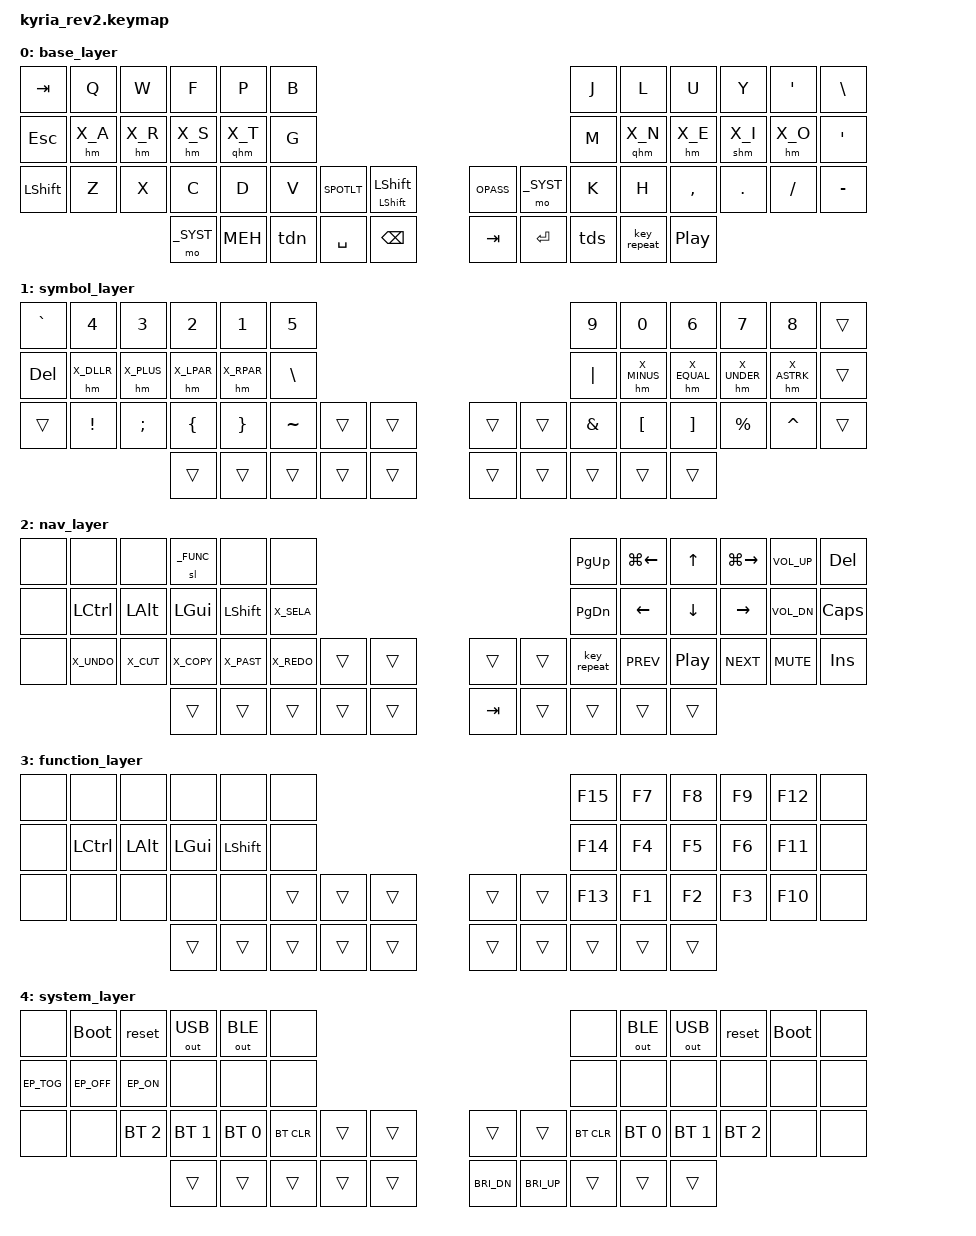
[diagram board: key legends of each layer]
/*
 * Copyright (c) 2020 The ZMK Contributors
 *
 * SPDX-License-Identifier: MIT
 */

#include <behaviors.dtsi>
#include <dt-bindings/zmk/keys.h>
#include <dt-bindings/zmk/bt.h>
#include <dt-bindings/zmk/outputs.h>
#include <dt-bindings/zmk/ext_power.h>
#include "halcyoncorsair.h"

// Encoder resolutions
&left_encoder   { resolution = <2>; };
&right_encoder  { resolution = <2>; };

&lt {
    tapping-term-ms = <250>;
    flavor = "tap-preferred";
};

&mt {
    tapping-term-ms = <200>;
};

&sk {
     release-after-ms = <1000>;
     quick-release;
};

&sl {
    /delete-property/ quick-release;
};

&caps_word {
    continue-list = <UNDERSCORE MINUS PIPE>; // BSPC
};

/ {
    behaviors {
        bhm: balanced_homerow_mods {
            compatible = "zmk,behavior-hold-tap";
            label = "HOMEROW_MODS";
            #binding-cells = <2>;
            tapping-term-ms = <200>;    // <---[[moderate duration]]
            quick-tap-ms = <0>;
            flavor = "balanced";
            bindings = <&kp>, <&kp>;
        };
        shm: homerow_mods {
            compatible = "zmk,behavior-hold-tap";
            label = "HOMEROW_MODS";
            #binding-cells = <2>;
            tapping-term-ms = <300>;
            quick-tap-ms = <0>;
            flavor = "tap-preferred";
            bindings = <&kp>, <&kp>;
        };
        hm: homerow_mods {
            compatible = "zmk,behavior-hold-tap";
            label = "HOMEROW_MODS";
            #binding-cells = <2>;
            tapping-term-ms = <250>;
            quick-tap-ms = <0>;
            flavor = "tap-preferred";
            bindings = <&kp>, <&kp>;
        };
        qhm: homerow_mods {
            compatible = "zmk,behavior-hold-tap";
            label = "QUICK_HOMEROW_MODS";
            #binding-cells = <2>;
            tapping-term-ms = <200>;
            quick-tap-ms = <0>;
            flavor = "tap-preferred";
            bindings = <&kp>, <&kp>;
        };
        ss: sticky_shift {
            compatible = "zmk,behavior-hold-tap";
            label = "STICKY_SHIFT";
            #binding-cells = <2>;
            tapping-term-ms = <150>;
            quick-tap-ms = <0>;
            flavor = "tap-preferred";
            bindings = <&kp>, <&sk>;
        };
		tdn: tap_dance_navi {
            compatible = "zmk,behavior-tap-dance";
            label = "TAP_DANCE_NAVI";
            #binding-cells = <0>;
            tapping-term-ms = <200>;
            bindings = <&mo _NAVI>, <&tog _NAVI>;
        };
		tds: tap_dance_symb {
            compatible = "zmk,behavior-tap-dance";
            label = "TAP_DANCE_SYMB";
            #binding-cells = <0>;
            tapping-term-ms = <200>;
            bindings = <&mo _SYMB>, <&tog _SYMB>;
        };
    };

    combos {
        #include "kyria_combos.def"
    };

	keymap {
		compatible = "zmk,keymap";
/*
// ---------------------------------------------------------------------------------------------------------------------------------
// |  ESC  |  Q  |  W  |  E   |  R   |  T   |                                          |  Y   |  U    |  I    |  O   |   P   |   \  |
// |  TAB  |  A  |  S  |  D   |  F   |  G   |                                          |  H   |  J    |  K    |  L   |   ;   |   '  |
// | SHIFT |  Z  |  X  |  C   |  V   |  B   | L SHIFT | L SHIFT |  | L SHIFT | L SHIFT |  N   |  M    |  ,    |  .   |   /   | CTRL |
//                     | GUI  | DEL  | RET  |  SPACE  |   ESC   |  |   RET   |  SPACE  | TAB  | BSPC  | R-ALT |
 */

        base_layer {
            bindings = <
    &kp TAB    &kp Q       &kp W       &kp F       &kp P       &kp B                                                                          &kp J       &kp L       &kp U           &kp Y         &kp SQT        &kp BSLH
    &kp ESC    &hm X_A     &hm X_R     &hm X_S     &qhm X_T    &kp G                                                                          &kp M       &qhm X_N    &hm X_E         &shm X_I       &hm X_O        &kp SQT
    &kp LSHFT  &kp Z       &kp X       &kp C       &kp D       &kp V       &kp SPOTLT &ss LSHIFT LSHIFT            &kp OPASS     &mo _SYST    &kp K       &kp H       &kp COMMA       &kp DOT       &kp FSLH       &kp MINUS
                                       &mo _SYST   &kp MEH     &tdn        &kp SPC       &kp BSPC                  &kp TAB       &kp ENTER    &tds        &key_repeat &kp C_PLAY_PAUSE
            >;

			sensor-bindings = <&inc_dec_kp PG_DN PG_UP &inc_dec_kp C_VOL_DN C_VOL_UP>;
		};
        symbol_layer {
            bindings = <
    &kp GRAVE  &kp N4      &kp N3      &kp N2      &kp N1      &kp N5                                                                         &kp N9       &kp N0      &kp N6         &kp N7         &kp N8        &trans
    &kp DEL    &hm X_DLLR  &hm X_PLUS  &hm X_LPAR  &hm X_RPAR  &kp BSLH                                                                       &kp PIPE     &hm X_MINUS &hm X_EQUAL    &hm X_UNDER    &hm X_ASTRK   &trans
    &trans     &kp EXCL    &kp SEMI    &kp LBRC    &kp RBRC    &kp TILDE   &trans  &trans                          &trans        &trans       &kp AMPS     &kp LBKT    &kp RBKT       &kp PERCENT    &kp CARET     &trans
                                       &trans      &trans      &trans      &trans  &trans                          &trans        &trans       &trans       &trans      &trans
            >;

			sensor-bindings = <&inc_dec_kp C_VOL_DN C_VOL_UP &inc_dec_kp PG_DN PG_UP>;
		};
        nav_layer {
            bindings = <
    &none      &none       &none       &sl _FUNC   &none       &none                                                                           &kp PG_UP   &kp LG(LEFT) &kp UP         &kp LG(RIGHT) &kp C_VOL_UP  &kp DEL
    &none      &kp LCTRL   &kp LALT    &kp LGUI    &kp LSHFT   &kp X_SELA                                                                      &kp PG_DN   &kp LEFT     &kp DOWN       &kp RIGHT     &kp C_VOL_DN  &kp CAPS
    &none      &kp X_UNDO  &kp X_CUT   &kp X_COPY  &kp X_PAST  &kp X_REDO  &trans  &trans                          &trans        &trans        &key_repeat &kp C_PREV   &kp C_PP       &kp C_NEXT    &kp C_MUTE    &kp INS
                                       &trans      &trans      &trans      &trans  &trans                          &kp TAB       &trans        &trans      &trans       &trans
            >;

			sensor-bindings = <&inc_dec_kp C_VOL_DN C_VOL_UP &inc_dec_kp PG_DN PG_UP>;
		};
        function_layer {
            bindings = <
    &none      &none       &none       &none       &none       &none                                                                           &kp F15     &kp F7        &kp F8        &kp F9        &kp F12       &none
    &none      &kp LCTRL   &kp LALT    &kp LGUI    &kp LSHFT   &none                                                                           &kp F14     &kp F4        &kp F5        &kp F6        &kp F11       &none
    &none      &none       &none       &none       &none       &trans     &trans  &trans                           &trans        &trans        &kp F13     &kp F1        &kp F2        &kp F3        &kp F10       &none
                                       &trans      &trans      &trans     &trans  &trans                           &trans        &trans        &trans      &trans        &trans
            >;

			sensor-bindings = <&inc_dec_kp C_VOL_DN C_VOL_UP &inc_dec_kp PG_UP PG_DN>;
                };
        system_layer {
            bindings = <
    &none      &bootloader &reset        &out OUT_USB  &out OUT_BLE  &none                                                               &none       &out OUT_BLE  &out OUT_USB  &reset        &bootloader   &none
    &kp EP_TOG &kp EP_OFF  &kp EP_ON     &none         &none         &none                                                               &none       &none         &none         &none         &none         &none
    &none      &none       &bt BT_SEL 2  &bt BT_SEL 1  &bt BT_SEL 0  &bt BT_CLR  &trans  &trans              &trans        &trans        &bt BT_CLR  &bt BT_SEL 0  &bt BT_SEL 1  &bt BT_SEL 2  &none         &none
                                         &trans        &trans        &trans      &trans  &trans              &kp C_BRI_DN  &kp C_BRI_UP  &trans      &trans        &trans
             >;

			sensor-bindings = <&inc_dec_kp C_VOL_DN C_VOL_UP &inc_dec_kp PG_UP PG_DN>;
		};
	};
};
